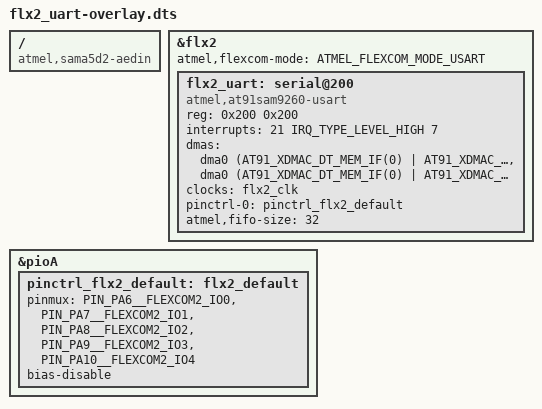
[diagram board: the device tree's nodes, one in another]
/*
 * Device Tree overlay for the AEMICS DIN module processing board
 *
 * Configures flx2 for UART
 *
 *  Copyright (C) 2016 AEMICS
 */
/dts-v1/;
/plugin/;

#include "../sama5d2-pinfunc.h"
#include <dt-bindings/mfd/atmel-flexcom.h>
#include <dt-bindings/gpio/gpio.h>
#include <dt-bindings/dma/at91.h>
#include <dt-bindings/interrupt-controller/irq.h>
#include <dt-bindings/clock/at91.h>

/{
	compatible = "atmel,sama5d2-aedin", "atmel,sama5d2", "atmel,sama5";

	fragment@0 {
		target = <&flx2>;
		__overlay__ {
			#address-cells = <1>;
			#size-cells = <1>;
			atmel,flexcom-mode = <ATMEL_FLEXCOM_MODE_USART>;
			status = "okay";
			flx2_uart: serial@200 {
				compatible = "atmel,at91sam9260-usart";
				reg = <0x200 0x200>;
				interrupts = <21 IRQ_TYPE_LEVEL_HIGH 7>;
				dmas = <&dma0
				(AT91_XDMAC_DT_MEM_IF(0) | AT91_XDMAC_DT_PER_IF(1) |
				 AT91_XDMAC_DT_PERID(15))>,
				   <&dma0
				(AT91_XDMAC_DT_MEM_IF(0) | AT91_XDMAC_DT_PER_IF(1) |
				 AT91_XDMAC_DT_PERID(16))>;
				dma-names = "tx", "rx";
				clocks = <&flx2_clk>;
				clock-names = "usart";
				pinctrl-names = "default";
				pinctrl-0 = <&pinctrl_flx2_default>;
				atmel,fifo-size = <32>;
				status = "okay";
			};
		};
	};
	
	fragment@1 {
		target = <&pioA>;
		__overlay__ {
			pinctrl_flx2_default: flx2_default {
				pinmux = <PIN_PA6__FLEXCOM2_IO0>,
					 <PIN_PA7__FLEXCOM2_IO1>,
					 <PIN_PA8__FLEXCOM2_IO2>,
					 <PIN_PA9__FLEXCOM2_IO3>,
					 <PIN_PA10__FLEXCOM2_IO4>;
				bias-disable;
			};
		};
	};
};
